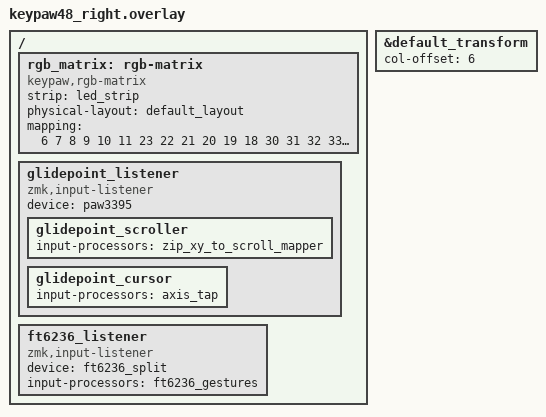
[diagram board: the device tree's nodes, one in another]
/*
 * Copyright (c) 2026 The ZMK Contributors
 * SPDX-License-Identifier: MIT
 */

#include <input/processors.dtsi>
#include <dt-bindings/keypaw/rgb_matrix.h>

#include "keypaw48.dtsi"
#include "kp-peri_right.dtsi"

&default_transform {
    col-offset = <6>;
};

/ {
    rgb_matrix: rgb-matrix {
        compatible = "keypaw,rgb-matrix";
        strip = <&led_strip>;
        physical-layout = <&default_layout>;

        mapping = <
        6 7 8 9 10 11
        23 22 21 20 19 18
        30 31 32 33 34 35

        KP_RGB_NO_KEY(1450, 387) // between 35 & 47
        KP_RGB_NO_KEY(1350, 387) // between 34 & 46
        KP_RGB_NO_KEY(1250, 400) // ~to the left of the previous LED
        KP_RGB_NO_KEY(1180, 350) // ~to the top left of the previous LED
        47 46
        KP_RGB_NO_KEY(1000, 500) // ~to the right of 42
        42
        KP_RGB_NO_KEY(850, 475)  // ~to the left of 42
        43 44 45
        >;
    };

    glidepoint_listener {
        compatible = "zmk,input-listener";
        device = <&paw3395>;
        glidepoint_scroller: glidepoint_scroller {
            // layers = specified in keypaw48.keymap;
            input-processors = <&zip_xy_to_scroll_mapper>;
        };
        glidepoint_cursor: glidepoint_cursor {
            // layers = specified in keypaw48.keymap;
            input-processors = <&axis_tap>;
        };
    };

    ft6236_listener: ft6236_listener {
        compatible = "zmk,input-listener";
        device = <&ft6236_split>;

        /* The driver does not report touch coordinates, and this chain exists
         * purely to map gesture codes onto behaviours (table in the keymap). */
        input-processors = <&ft6236_gestures>;
    };
};
